# AC78xx register map
Vendor: AutoChips; Series: AC78xx; File version: 1.0
CPU: CM3 r2p1, little endian, MPU, no FPU, 3 interrupt priority bits
Registers are 32-bit, read-write, no defined reset value unless marked. A register's access mark holds for its fields unless they carry their own. Offsets are from the block's base; [hi:lo] are bit positions; lines under a group give offsets from that group; {n}, {i} and the like mark numbered series.

## CTU — Connect Module Unit
Base 0x40016000; register names take the prefix CTU_
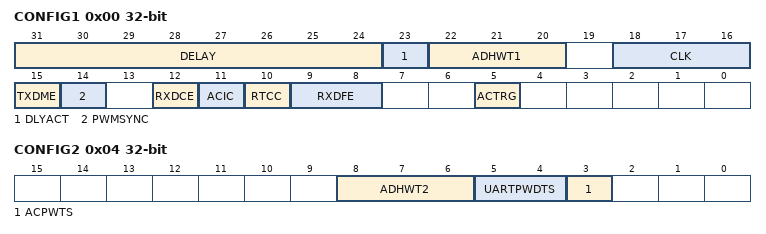
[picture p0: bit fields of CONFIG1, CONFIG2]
0x00 CONFIG1 — CTU Configuration Register 1
  [31:24] DELAY — Trigger Delay Counter
  [23] DLYACT — Trigger Delay Active
    0=Delay is inactive; 1=Delay is active
  [22:20] ADHWT1 — ADC Hardware Trigger Source for regular group
    0=RTC Overflow as ADC hardware Trigger; 1=PWM0 as ADC Hardware Trigger; 2=PWM2 Init Trigger with 8-bit programmable counter delay; 3=PWM2 Match Trigger with 8-bit programmable counter delay; 4=Timer Channel0 overflow as ADC Hardware Trigger; 5=Timer Channel1 overflow as ADC hardware Trigger; 6=ACMP0 Out as ADC Hardware Trigger; 7=ACMP1 Out as ADC Hardware Trigger
  [18:16] CLK — BUS Clock Output Selection
    0=BUS Clock; 1=Bus Divided by 2; 2=Bus Divided by 4; 3=Bus Divided by 8; 4=Bus Divided by 16; 5=Bus Divided by 32; 6=Bus Divided by 64; 7=Bus Divided by 128
  [15] TXDME — UART1 TX Modulation Selection
    0=UART1_TX is connected to PIN out directly; 1=UART1_TX is modulated by PWM0 Channel 0
  [14] PWMSYNC — PWM SW Synchronization Selection
    0=No Synchronization triggered; 1=Generate PWM Synchronization to trigger PWM Modules
  [12] RXDCE — UART0_RX Capture Selection
    0=UART1_RX input connect to UART1 Only; 1=UART1_RX input connected to PWM0 Channel 1
  [11] ACIC — Analog Comparator to Input Capture Enable
    0=ACMP0 Output is not connected to PWM1 Channel0; 1=ACMP1 Output is connected to PWM1 Channel0
  [10] RTCC — Real-Time Counter Capture
    0=RTC Overflow is not connected to PWM1 Channel 1; 1=RTC overflow is connected to PWM1 Channel 1
  [9:8] RXDFE — UART1 RxD filter Selection
    0=RXD1 input signal is connected to UART1 modulate directly; 1=RXD1 input signal is filtered by ACMP0, then injected to UART1; 2=RXD1 input signal is filtered by ACMP1, then injected to UART1; 3=Not Defined
  [5] ACTRG — ACMP Trigger PWM2 Selection
    0=ACMP0 Output Trigger PWM; 1=ACMP1 Output Trigger PWM
0x04 CONFIG2 — CTU Configuration Register 2
  [8:6] ADHWT2 — ADC Hardware Trigger Source for injection group
    0=RTC Overflow as the ADC hardware trigger; 1=PWM0 as the ADC hardware trigger; 2=PWM2 init trigger with 8-bit programmable count delay as ADC hardware trigger; 3=PWM2 match trigger with 8-bit programmable count delay as ADC hardware trigger; 4=Timer Channel0 overflow as the ADC hardware trigger; 5=Timer Channel1 overflow as the ADC hardware trigger; 6=ACMP0 output as the ADC hardware trigger; 7=ACMP1 output as the ADC hardware trigger
  [5:4] UARTPWDTS — PWDT UART RX Select
    0=UART0 RX is connected to PWDT_IN3; 1=UART1 RX is connected to PWDT_IN3; 2=UART2 RX is connected to PWDT_IN3; 3=ACMP_OUT is Connected to PWTIN3
  [3] ACPWTS — PWDT ACMP_OUT Select
    0=ACMP1_OUT is Connected to PWDT_IN3; 1=ACMP0_OUT is Connected to PWDT_IN3

## DMA0_TOP_RST — DMA0 All Channnels Share The Registers
Base 0x40012000
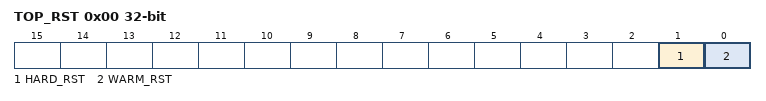
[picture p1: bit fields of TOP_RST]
0x00 TOP_RST
  [1] HARD_RST — hard reset
  [0] WARM_RST — warm reset

## DMA1 — DMA channel 1
Base 0x40012040
Same registers: DMA{n} {0x40012000+0x40*n} (n=2..12)
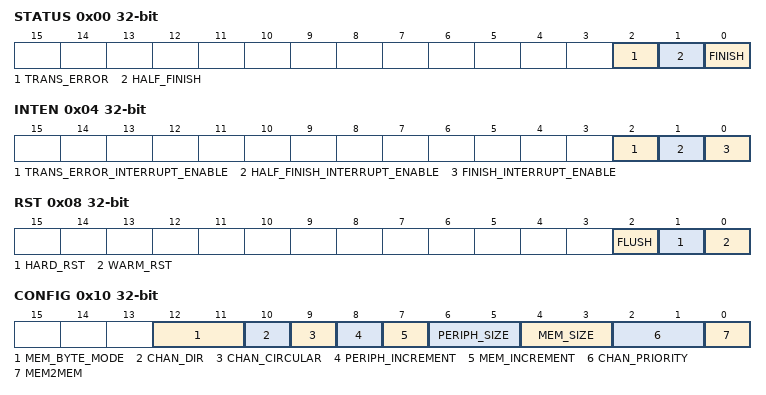
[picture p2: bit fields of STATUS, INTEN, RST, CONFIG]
0x00 STATUS
  [2] TRANS_ERROR — transfer error flag
  [1] HALF_FINISH — transfer half finished flag
  [0] FINISH — transfer finished flag
0x04 INTEN — Interrupt Enable Register
  [2] TRANS_ERROR_INTERRUPT_ENABLE — transfer error interrupt enable or disable
  [1] HALF_FINISH_INTERRUPT_ENABLE — transfer half finished interrupt enable or disable
  [0] FINISH_INTERRUPT_ENABLE — transfer finished interrupt enable or disable
0x08 RST — Reset Register
  [2] FLUSH — dma flush enable or disable
  [1] HARD_RST — hard reset enable or disable
  [0] WARM_RST — warm reset enable or disable
0x0C STOP
  [0] STOP — DMA channel stop enable or disable
0x10 CONFIG — DMA Config Register
  [12:11] MEM_BYTE_MODE — memory word segmentation transfer number
  [10] CHAN_DIR — channel read data direction select
    0=READ_FROM_PERIPH (DMA read from peripheral); 1=READ_FROM_MEM (DMA read from memory)
  [9] CHAN_CIRCULAR — channel circular mode enable or disable
  [8] PERIPH_INCREMENT — peripheral address increase or fix
  [7] MEM_INCREMENT — memory address increase or fix
  [6:5] PERIPH_SIZE — peripheral size select
    0=8BIT (PERIPH SIZE 8BIT); 1=16BIT (PERIPH SIZE 16BIT); 2=32BIT (PERIPH SIZE 32BIT)
  [4:3] MEM_SIZE — memory size select
    0=8BIT (MEM SIZE 8BIT); 1=16BIT (MEM SIZE 16BIT); 2=32BIT (MEM SIZE 32BIT)
  [2:1] CHAN_PRIORITY — channel priority select
    0=LOW (DMA channel priority low); 1=MEDIUM (DMA channel priority medium); 2=HIGH (DMA channel priority high); 3=VERY_HIGH (DMA channel priority very high)
  [0] MEM2MEM — memory to memory transfer enable or disable
0x14 CHAN_LENGTH — Channel Length Register
  [15:0] CHAN_LENGTH — DMA channel transfer length
0x18 MEM_START_ADDR — Memory Start Address Register
  [31:0] MEM_START_ADDR — memory start address
0x1C MEM_END_ADDR — Memory End Address Register
  [31:0] MEM_END_ADDR — set memory end address
0x20 PERIPH_ADDR — Peripheral Address Register
  [31:0] PERIPH_ADDR — set peripheral address
0x24 CHAN_ENABLE — Channel Enable Register
  [0] CHAN_ENABLE — channel enable
0x28 DATA_TRANS_NUM — Data Transfer Number Register
  [15:0] DATA_TRANS_NUM — data has been transfered number
0x2C FIFO_LEFT_NUM — Internal FIFO Data Left Number Register
  [5:0] FIFO_LEFT_NUM — internal fifo data left number
